# AST1080 register map
File version: 1.0
CPU: CM4 r0p1, little endian, MPU, FPU, 4 interrupt priority bits, 256 interrupts
Registers are 32-bit, read-write, reset 0x0 unless marked. A register's access mark holds for its fields unless they carry their own. Offsets are from the block's base; [hi:lo] are bit positions; {n}, {i} and the like mark numbered series.

## i3c
Base 0x74C20000
Same registers: i3c1 0x74C21000, i3c2 0x74C22000, i3c3 0x74C23000, i3c4 0x74C24000, i3c5 0x74C25000, i3c6 0x74C26000, i3c7 0x74C27000
0x00 HCICAPABILITY000 reset 0x110 — HCI\_VERSION
  [31:0] REGHCIVERSION ro
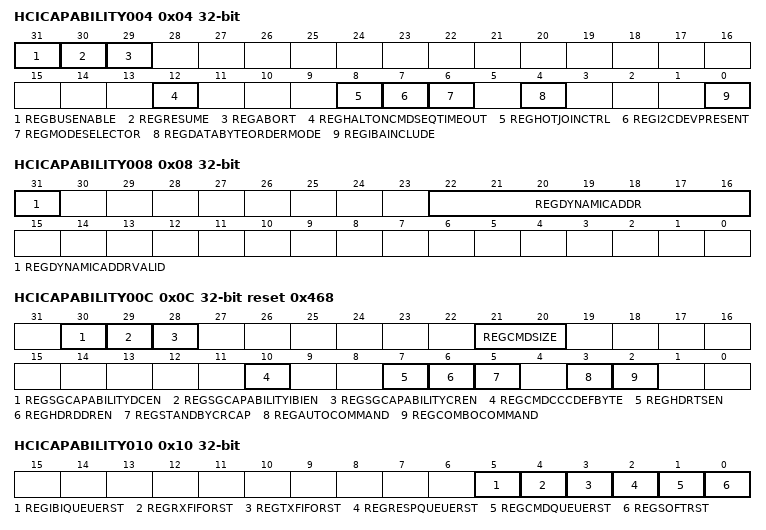
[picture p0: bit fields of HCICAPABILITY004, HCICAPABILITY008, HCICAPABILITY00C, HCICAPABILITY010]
0x04 HCICAPABILITY004 — HC\_CONTROL
  [31] REGBUSENABLE, [30] REGRESUME, [29] REGABORT, [12] REGHALTONCMDSEQTIMEOUT, [8] REGHOTJOINCTRL, [7] REGI2CDEVPRESENT, [6] REGMODESELECTOR, [4] REGDATABYTEORDERMODE ro, [0] REGIBAINCLUDE
0x08 HCICAPABILITY008 — CONTROLLER\_DEVICE\_ADDR
  [31] REGDYNAMICADDRVALID, [22:16] REGDYNAMICADDR
0x0C HCICAPABILITY00C reset 0x468 — HC\_CAPABILITIES
  [30] REGSGCAPABILITYDCEN ro, [29] REGSGCAPABILITYIBIEN ro, [28] REGSGCAPABILITYCREN ro, [21:20] REGCMDSIZE ro, [10] REGCMDCCCDEFBYTE ro, [7] REGHDRTSEN ro, [6] REGHDRDDREN ro, [5] REGSTANDBYCRCAP ro, [3] REGAUTOCOMMAND ro, [2] REGCOMBOCOMMAND ro
0x10 HCICAPABILITY010 — RESET\_CONTROL
  [5] REGIBIQUEUERST, [4] REGRXFIFORST, [3] REGTXFIFORST, [2] REGRESPQUEUERST, [1] REGCMDQUEUERST, [0] REGSOFTRST
0x14 HCICAPABILITY014 — PRESENT\_STATE
  [2] REGCURRENTCONTROLLER ro
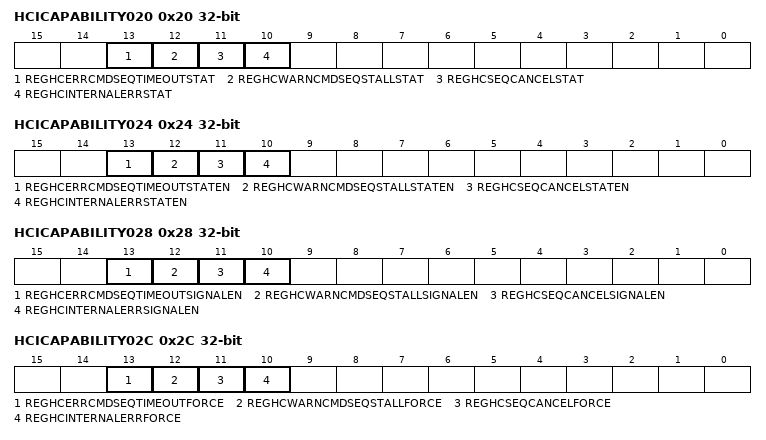
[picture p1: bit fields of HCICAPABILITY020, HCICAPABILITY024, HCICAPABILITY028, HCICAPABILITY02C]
0x20 HCICAPABILITY020 — INTR\_STATUS
  [13] REGHCERRCMDSEQTIMEOUTSTAT, [12] REGHCWARNCMDSEQSTALLSTAT, [11] REGHCSEQCANCELSTAT, [10] REGHCINTERNALERRSTAT
0x24 HCICAPABILITY024 — INTR\_STATUS\_ENABLE
  [13] REGHCERRCMDSEQTIMEOUTSTATEN, [12] REGHCWARNCMDSEQSTALLSTATEN, [11] REGHCSEQCANCELSTATEN, [10] REGHCINTERNALERRSTATEN
0x28 HCICAPABILITY028 — INTR\_SIGNAL\_ENABLE
  [13] REGHCERRCMDSEQTIMEOUTSIGNALEN, [12] REGHCWARNCMDSEQSTALLSIGNALEN, [11] REGHCSEQCANCELSIGNALEN, [10] REGHCINTERNALERRSIGNALEN
0x2C HCICAPABILITY02C — INTR\_FORCE
  [13] REGHCERRCMDSEQTIMEOUTFORCE, [12] REGHCWARNCMDSEQSTALLFORCE, [11] REGHCSEQCANCELFORCE, [10] REGHCINTERNALERRFORCE
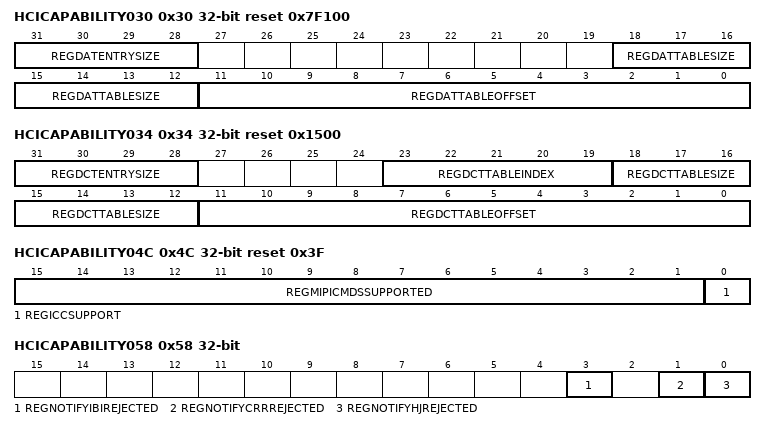
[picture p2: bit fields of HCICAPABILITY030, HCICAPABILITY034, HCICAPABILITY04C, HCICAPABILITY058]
0x30 HCICAPABILITY030 reset 0x7F100 — DAT\_SECTION\_OFFSET
  [31:28] REGDATENTRYSIZE ro, [18:12] REGDATTABLESIZE ro, [11:0] REGDATTABLEOFFSET ro
0x34 HCICAPABILITY034 reset 0x1500 — DCT\_SECTION\_OFFSET
  [31:28] REGDCTENTRYSIZE ro, [23:19] REGDCTTABLEINDEX, [18:12] REGDCTTABLESIZE ro, [11:0] REGDCTTABLEOFFSET ro
0x38 HCICAPABILITY038 reset 0x800 — RING\_HEADERS\_SECTION\_OFFSET
  [15:0] REGRINGHEADERSECTIONOFFSET ro
0x3C HCICAPABILITY03C reset 0xD0 — PIO\_SECTION\_OFFSET
  [15:0] REGPIOSECTIONOFFSET ro
0x40 HCICAPABILITY040 reset 0xF00 — EXT\_CAPS\_SECTION\_OFFSET
  [15:0] REGEXTCAPSSECTIONOFFSET ro
0x4C HCICAPABILITY04C reset 0x3F — INT\_CTRL\_CMDS\_EN
  [15:1] REGMIPICMDSSUPPORTED ro, [0] REGICCSUPPORT ro
0x58 HCICAPABILITY058 — IBI\_NOTIFY\_CTRL
  [3] REGNOTIFYIBIREJECTED, [1] REGNOTIFYCRRREJECTED, [0] REGNOTIFYHJREJECTED
0x60 HCICAPABILITY060 — DEV\_CTX\_BASE\_LO
  [31:0] REGDEVCTXBASELO
0x64 HCICAPABILITY064 — DEV\_CTX\_BASE\_HI
  [31:0] REGDEVCTXBASEHI
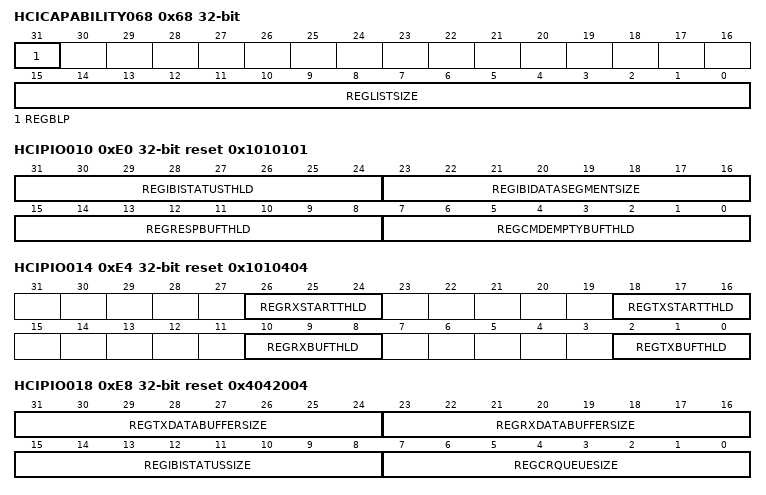
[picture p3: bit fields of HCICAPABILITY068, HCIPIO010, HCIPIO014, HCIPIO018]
0x68 HCICAPABILITY068 — DEV\_CTX\_SG
  [31] REGBLP, [15:0] REGLISTSIZE
0xD0 HCIPIO000 — COMMAND\_QUEUE\_PORT
  [31:0] REGCOMMANDQUEUEPORT
0xD4 HCIPIO004 — RESPONSE\_QUEUE\_PORT
  [31:0] REGRESPONSEQUEUEPORT ro
0xD8 HCIPIO008 — XFER\_DATA\_PORT
  [31:0] REGDATAPORT
0xDC HCIPIO00C — IBI\_PORT
  [31:0] REGIBIPORT ro
0xE0 HCIPIO010 reset 0x1010101 — QUEUE\_THLD\_CTRL
  [31:24] REGIBISTATUSTHLD, [23:16] REGIBIDATASEGMENTSIZE, [15:8] REGRESPBUFTHLD, [7:0] REGCMDEMPTYBUFTHLD
0xE4 HCIPIO014 reset 0x1010404 — DATA\_BUFFER\_THLD\_CTRL
  [26:24] REGRXSTARTTHLD, [18:16] REGTXSTARTTHLD, [10:8] REGRXBUFTHLD, [2:0] REGTXBUFTHLD
0xE8 HCIPIO018 reset 0x4042004 — QUEUE\_SIZE
  [31:24] REGTXDATABUFFERSIZE ro, [23:16] REGRXDATABUFFERSIZE ro, [15:8] REGIBISTATUSSIZE ro, [7:0] REGCRQUEUESIZE ro
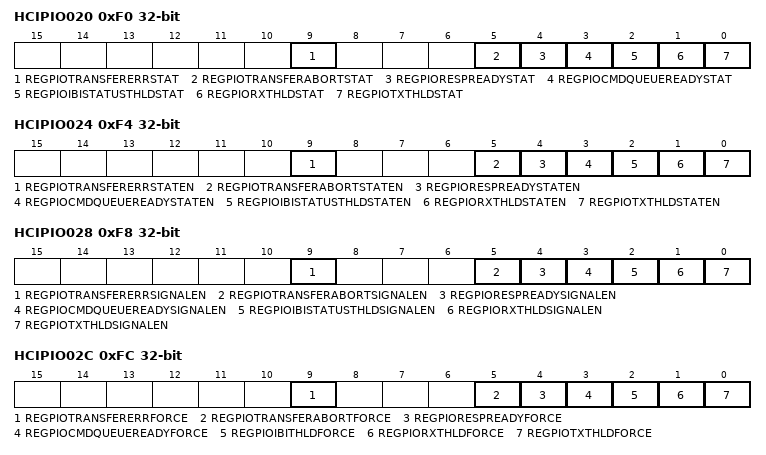
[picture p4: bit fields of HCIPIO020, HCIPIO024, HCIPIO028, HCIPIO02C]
0xF0 HCIPIO020 — PIO\_INTR\_STATUS
  [9] REGPIOTRANSFERERRSTAT, [5] REGPIOTRANSFERABORTSTAT, [4] REGPIORESPREADYSTAT ro, [3] REGPIOCMDQUEUEREADYSTAT ro, [2] REGPIOIBISTATUSTHLDSTAT ro, [1] REGPIORXTHLDSTAT ro, [0] REGPIOTXTHLDSTAT ro
0xF4 HCIPIO024 — PIO\_INTR\_STATUS\_ENABLE
  [9] REGPIOTRANSFERERRSTATEN, [5] REGPIOTRANSFERABORTSTATEN, [4] REGPIORESPREADYSTATEN, [3] REGPIOCMDQUEUEREADYSTATEN, [2] REGPIOIBISTATUSTHLDSTATEN, [1] REGPIORXTHLDSTATEN, [0] REGPIOTXTHLDSTATEN
0xF8 HCIPIO028 — PIO\_INTR\_SIGNAL\_ENABLE
  [9] REGPIOTRANSFERERRSIGNALEN, [5] REGPIOTRANSFERABORTSIGNALEN, [4] REGPIORESPREADYSIGNALEN, [3] REGPIOCMDQUEUEREADYSIGNALEN, [2] REGPIOIBISTATUSTHLDSIGNALEN, [1] REGPIORXTHLDSIGNALEN, [0] REGPIOTXTHLDSIGNALEN
0xFC HCIPIO02C — PIO\_INTR\_FORCE
  [9] REGPIOTRANSFERERRFORCE, [5] REGPIOTRANSFERABORTFORCE, [4] REGPIORESPREADYFORCE, [3] REGPIOCMDQUEUEREADYFORCE, [2] REGPIOIBITHLDFORCE, [1] REGPIORXTHLDFORCE, [0] REGPIOTXTHLDFORCE
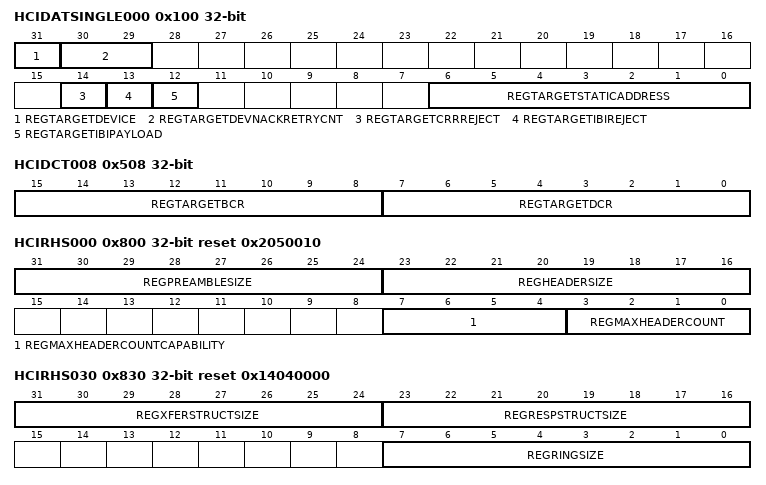
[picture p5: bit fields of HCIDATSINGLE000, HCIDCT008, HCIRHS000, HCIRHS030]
0x100 HCIDATSINGLE000 — TARGET\_DAT
  [31] REGTARGETDEVICE, [30:29] REGTARGETDEVNACKRETRYCNT, [14] REGTARGETCRRREJECT, [13] REGTARGETIBIREJECT, [12] REGTARGETIBIPAYLOAD, [6:0] REGTARGETSTATICADDRESS
0x500 HCIDCT000 — TARGET\_DCT\_0
  [31:0] REGTARGETPIDHI ro
0x504 HCIDCT004 — TARGET\_DCT\_1
  [15:0] REGTARGETPIDLO ro
0x508 HCIDCT008 — TARGET\_DCT\_2
  [15:8] REGTARGETBCR ro, [7:0] REGTARGETDCR ro
0x50C HCIDCT00C — TARGET\_DCT\_3
  [7:0] REGTARGETDYNAMICADDRESS ro
0x800 HCIRHS000 reset 0x2050010 — RHS\_CONTROL
  [31:24] REGPREAMBLESIZE ro, [23:16] REGHEADERSIZE ro, [7:4] REGMAXHEADERCOUNTCAPABILITY ro, [3:0] REGMAXHEADERCOUNT
0x804 HCIRHS004 reset 0x830 — RH0\_OFFSET
  [31:0] REGRH0OFFSET ro
0x830 HCIRHS030 reset 0x14040000 — CR\_SETUP
  [31:24] REGXFERSTRUCTSIZE ro, [23:16] REGRESPSTRUCTSIZE ro, [7:0] REGRINGSIZE
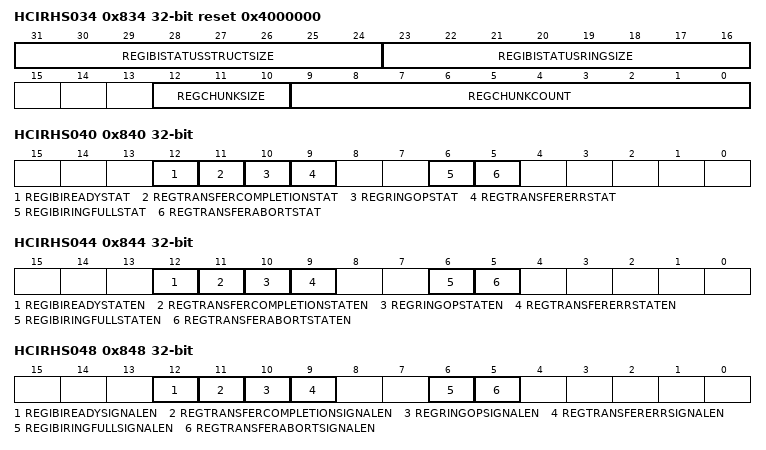
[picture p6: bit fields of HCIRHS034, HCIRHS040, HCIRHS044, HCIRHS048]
0x834 HCIRHS034 reset 0x4000000 — IBI\_SETUP
  [31:24] REGIBISTATUSSTRUCTSIZE ro, [23:16] REGIBISTATUSRINGSIZE, [12:10] REGCHUNKSIZE, [9:0] REGCHUNKCOUNT
0x838 HCIRHS038 — CHUNK\_CONTROL
  [31:0] REGCHUNKCOUNTER
0x840 HCIRHS040 — RH\_INTR\_STATUS
  [12] REGIBIREADYSTAT, [11] REGTRANSFERCOMPLETIONSTAT, [10] REGRINGOPSTAT, [9] REGTRANSFERERRSTAT, [6] REGIBIRINGFULLSTAT, [5] REGTRANSFERABORTSTAT
0x844 HCIRHS044 — RH\_INTR\_STATUS\_ENABLE
  [12] REGIBIREADYSTATEN, [11] REGTRANSFERCOMPLETIONSTATEN, [10] REGRINGOPSTATEN, [9] REGTRANSFERERRSTATEN, [6] REGIBIRINGFULLSTATEN, [5] REGTRANSFERABORTSTATEN
0x848 HCIRHS048 — RH\_INTR\_SIGNAL\_ENABLE
  [12] REGIBIREADYSIGNALEN, [11] REGTRANSFERCOMPLETIONSIGNALEN, [10] REGRINGOPSIGNALEN, [9] REGTRANSFERERRSIGNALEN, [6] REGIBIRINGFULLSIGNALEN, [5] REGTRANSFERABORTSIGNALEN
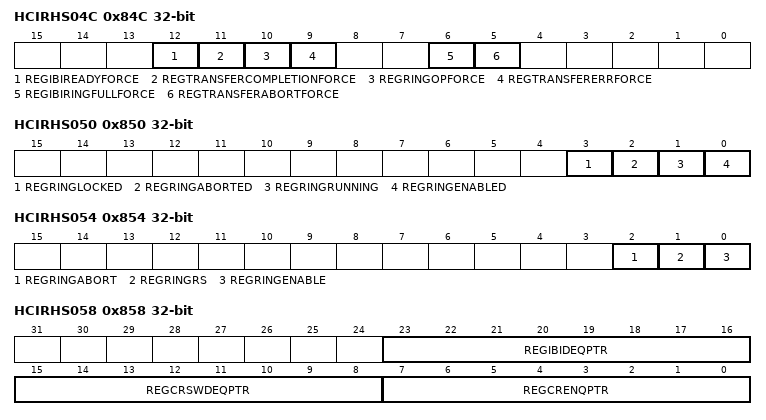
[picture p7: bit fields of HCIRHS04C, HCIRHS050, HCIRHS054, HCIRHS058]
0x84C HCIRHS04C — RH\_INTR\_FORCE
  [12] REGIBIREADYFORCE, [11] REGTRANSFERCOMPLETIONFORCE, [10] REGRINGOPFORCE, [9] REGTRANSFERERRFORCE, [6] REGIBIRINGFULLFORCE, [5] REGTRANSFERABORTFORCE
0x850 HCIRHS050 — RH\_STATUS
  [3] REGRINGLOCKED ro, [2] REGRINGABORTED ro, [1] REGRINGRUNNING ro, [0] REGRINGENABLED ro
0x854 HCIRHS054 — RH\_CONTROL
  [2] REGRINGABORT, [1] REGRINGRS, [0] REGRINGENABLE
0x858 HCIRHS058 — RH\_OPERATION1
  [23:16] REGIBIDEQPTR, [15:8] REGCRSWDEQPTR, [7:0] REGCRENQPTR
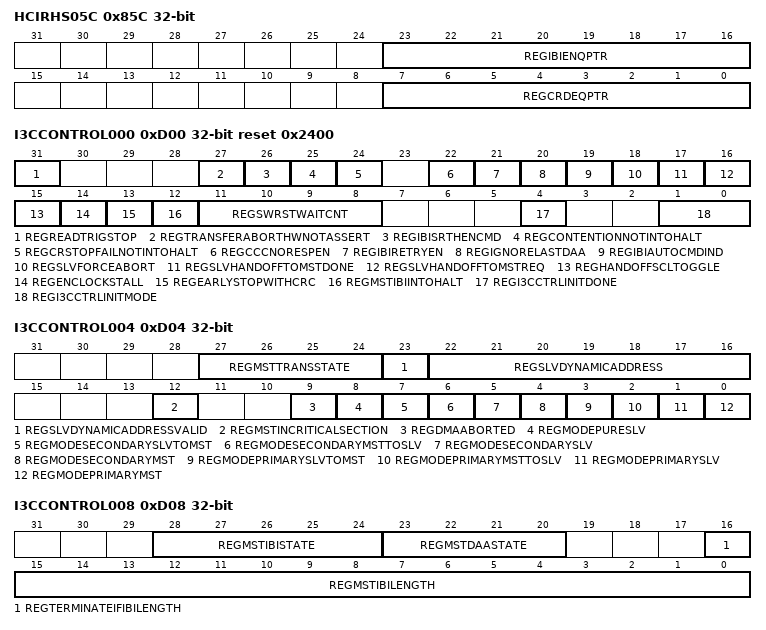
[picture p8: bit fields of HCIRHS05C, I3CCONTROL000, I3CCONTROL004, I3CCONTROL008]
0x85C HCIRHS05C — RH\_OPERATION2
  [23:16] REGIBIENQPTR ro, [7:0] REGCRDEQPTR ro
0x860 HCIRHS060 — RH\_CMD\_RING\_BASE\_LO
  [31:0] REGCMDRINGBASELO
0x864 HCIRHS064 — RH\_CMD\_RING\_BASE\_HI
  [31:0] REGCMDRINGBASEHI
0x868 HCIRHS068 — RH\_RESP\_RING\_BASE\_LO
  [31:0] REGRESPRINGBASELO
0x86C HCIRHS06C — RH\_RESP\_RING\_BASE\_HI
  [31:0] REGRESPRINGBASEHI
0x870 HCIRHS070 — RH\_IBI\_STATUS\_RING\_BASE\_LO
  [31:0] REGIBISTATUSRINGBASELO
0x874 HCIRHS074 — RH\_IBI\_STATUS\_RING\_BASE\_HI
  [31:0] REGIBISTATUSRINGBASEHI
0x878 HCIRHS078 — RH\_IBI\_DATA\_RING\_BASE\_LO
  [31:0] REGIBIDATARINGBASELO
0x87C HCIRHS07C — RH\_IBI\_DATA\_RING\_BASE\_HI
  [31:0] REGIBIDATARINGBASEHI
0xD00 I3CCONTROL000 reset 0x2400 — I3C\_CONTROL\_0
  [31] REGREADTRIGSTOP, [27] REGTRANSFERABORTHWNOTASSERT, [26] REGIBISRTHENCMD, [25] REGCONTENTIONNOTINTOHALT, [24] REGCRSTOPFAILNOTINTOHALT, [22] REGCCCNORESPEN, [21] REGIBIRETRYEN, [20] REGIGNORELASTDAA, [19] REGIBIAUTOCMDIND, [18] REGSLVFORCEABORT, [17] REGSLVHANDOFFTOMSTDONE ro, [16] REGSLVHANDOFFTOMSTREQ, [15] REGHANDOFFSCLTOGGLE, [14] REGENCLOCKSTALL, [13] REGEARLYSTOPWITHCRC, [12] REGMSTIBIINTOHALT, [11:8] REGSWRSTWAITCNT, [4] REGI3CCTRLINITDONE, [1:0] REGI3CCTRLINITMODE
0xD04 I3CCONTROL004 — I3C\_STATUS
  [27:24] REGMSTTRANSSTATE ro, [23] REGSLVDYNAMICADDRESSVALID ro, [22:16] REGSLVDYNAMICADDRESS ro, [12] REGMSTINCRITICALSECTION ro, [9] REGDMAABORTED ro, [8] REGMODEPURESLV ro, [7] REGMODESECONDARYSLVTOMST ro, [6] REGMODESECONDARYMSTTOSLV ro, [5] REGMODESECONDARYSLV ro, [4] REGMODESECONDARYMST ro, [3] REGMODEPRIMARYSLVTOMST ro, [2] REGMODEPRIMARYMSTTOSLV ro, [1] REGMODEPRIMARYSLV ro, [0] REGMODEPRIMARYMST ro
0xD08 I3CCONTROL008 — I3C\_MST\_MRL
  [28:24] REGMSTIBISTATE ro, [23:20] REGMSTDAASTATE ro, [16] REGTERMINATEIFIBILENGTH, [15:0] REGMSTIBILENGTH
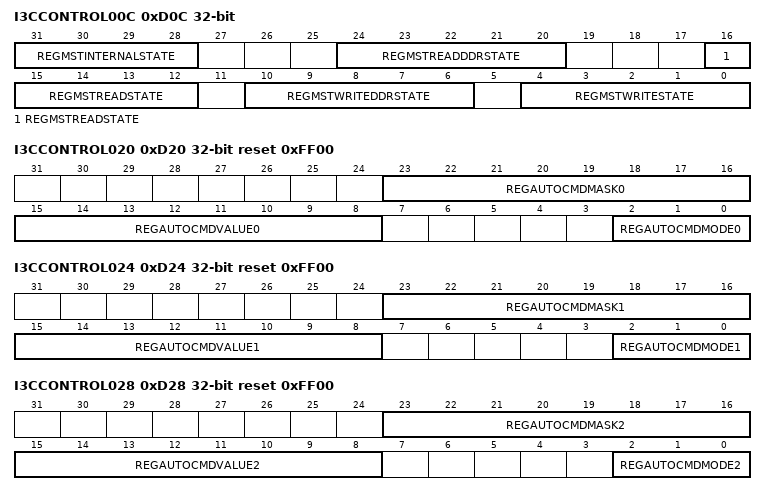
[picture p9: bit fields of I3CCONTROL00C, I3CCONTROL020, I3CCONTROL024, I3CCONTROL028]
0xD0C I3CCONTROL00C — I3C\_STATUS\_C
  [31:28] REGMSTINTERNALSTATE ro, [24:20] REGMSTREADDDRSTATE ro, [16:12] REGMSTREADSTATE ro, [10:6] REGMSTWRITEDDRSTATE ro, [4:0] REGMSTWRITESTATE ro
0xD10 I3CCONTROL010 — I3C\_DAA\_INDEX\_0
  [31:0] REGDAAPROCINDEX0
0xD14 I3CCONTROL014 — I3C\_DAA\_INDEX\_1
  [31:0] REGDAAPROCINDEX1
0xD18 I3CCONTROL018 — I3C\_DAA\_INDEX\_2
  [31:0] REGDAAPROCINDEX2
0xD1C I3CCONTROL01C — I3C\_DAA\_INDEX\_3
  [31:0] REGDAAPROCINDEX3
0xD20 I3CCONTROL020 reset 0xFF00 — I3C\_AUTOCMD\_0
  [23:16] REGAUTOCMDMASK0, [15:8] REGAUTOCMDVALUE0, [2:0] REGAUTOCMDMODE0
0xD24 I3CCONTROL024 reset 0xFF00 — I3C\_AUTOCMD\_1
  [23:16] REGAUTOCMDMASK1, [15:8] REGAUTOCMDVALUE1, [2:0] REGAUTOCMDMODE1
0xD28 I3CCONTROL028 reset 0xFF00 — I3C\_AUTOCMD\_2
  [23:16] REGAUTOCMDMASK2, [15:8] REGAUTOCMDVALUE2, [2:0] REGAUTOCMDMODE2
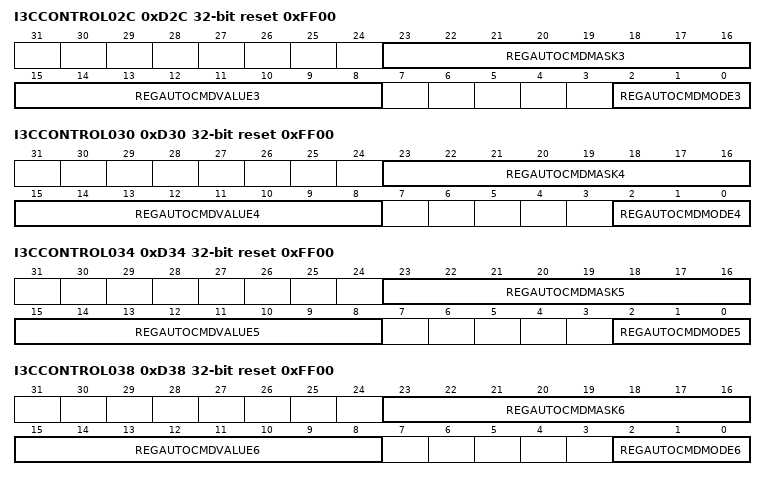
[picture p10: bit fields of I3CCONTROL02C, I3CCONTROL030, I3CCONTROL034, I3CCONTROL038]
0xD2C I3CCONTROL02C reset 0xFF00 — I3C\_AUTOCMD\_3
  [23:16] REGAUTOCMDMASK3, [15:8] REGAUTOCMDVALUE3, [2:0] REGAUTOCMDMODE3
0xD30 I3CCONTROL030 reset 0xFF00 — I3C\_AUTOCMD\_4
  [23:16] REGAUTOCMDMASK4, [15:8] REGAUTOCMDVALUE4, [2:0] REGAUTOCMDMODE4
0xD34 I3CCONTROL034 reset 0xFF00 — I3C\_AUTOCMD\_5
  [23:16] REGAUTOCMDMASK5, [15:8] REGAUTOCMDVALUE5, [2:0] REGAUTOCMDMODE5
0xD38 I3CCONTROL038 reset 0xFF00 — I3C\_AUTOCMD\_6
  [23:16] REGAUTOCMDMASK6, [15:8] REGAUTOCMDVALUE6, [2:0] REGAUTOCMDMODE6
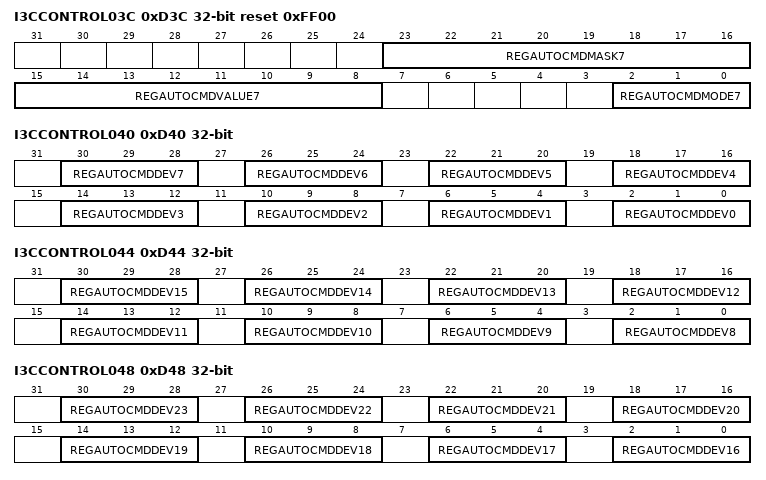
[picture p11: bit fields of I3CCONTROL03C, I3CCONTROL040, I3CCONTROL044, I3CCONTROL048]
0xD3C I3CCONTROL03C reset 0xFF00 — I3C\_AUTOCMD\_7
  [23:16] REGAUTOCMDMASK7, [15:8] REGAUTOCMDVALUE7, [2:0] REGAUTOCMDMODE7
0xD40 I3CCONTROL040 — I3C\_AUTOCMD\_SEL\_040
  [4n+2:4n] REGAUTOCMDDEV{n} (n=0..7)
0xD44 I3CCONTROL044 — I3C\_AUTOCMD\_SEL\_044
  [4n-30:4n-32] REGAUTOCMDDEV{n} (n=8..15)
0xD48 I3CCONTROL048 — I3C\_AUTOCMD\_SEL\_048
  [4n-62:4n-64] REGAUTOCMDDEV{n} (n=16..23)
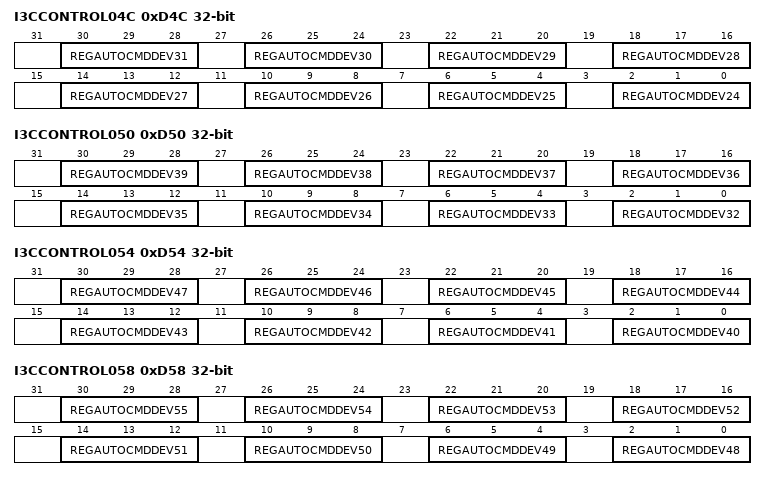
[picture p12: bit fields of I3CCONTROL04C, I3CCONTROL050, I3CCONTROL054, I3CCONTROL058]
0xD4C I3CCONTROL04C — I3C\_AUTOCMD\_SEL\_04C
  [4n-94:4n-96] REGAUTOCMDDEV{n} (n=24..31)
0xD50 I3CCONTROL050 — I3C\_AUTOCMD\_SEL\_050
  [4n-126:4n-128] REGAUTOCMDDEV{n} (n=32..39)
0xD54 I3CCONTROL054 — I3C\_AUTOCMD\_SEL\_054
  [4n-158:4n-160] REGAUTOCMDDEV{n} (n=40..47)
0xD58 I3CCONTROL058 — I3C\_AUTOCMD\_SEL\_058
  [4n-190:4n-192] REGAUTOCMDDEV{n} (n=48..55)
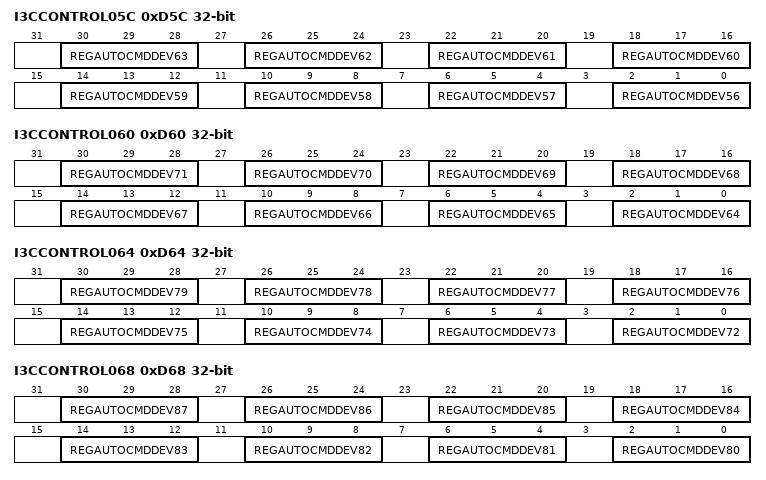
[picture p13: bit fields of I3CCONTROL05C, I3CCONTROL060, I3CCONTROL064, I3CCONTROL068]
0xD5C I3CCONTROL05C — I3C\_AUTOCMD\_SEL\_05C
  [4n-222:4n-224] REGAUTOCMDDEV{n} (n=56..63)
0xD60 I3CCONTROL060 — I3C\_AUTOCMD\_SEL\_060
  [4n-254:4n-256] REGAUTOCMDDEV{n} (n=64..71)
0xD64 I3CCONTROL064 — I3C\_AUTOCMD\_SEL\_064
  [4n-286:4n-288] REGAUTOCMDDEV{n} (n=72..79)
0xD68 I3CCONTROL068 — I3C\_AUTOCMD\_SEL\_068
  [4n-318:4n-320] REGAUTOCMDDEV{n} (n=80..87)
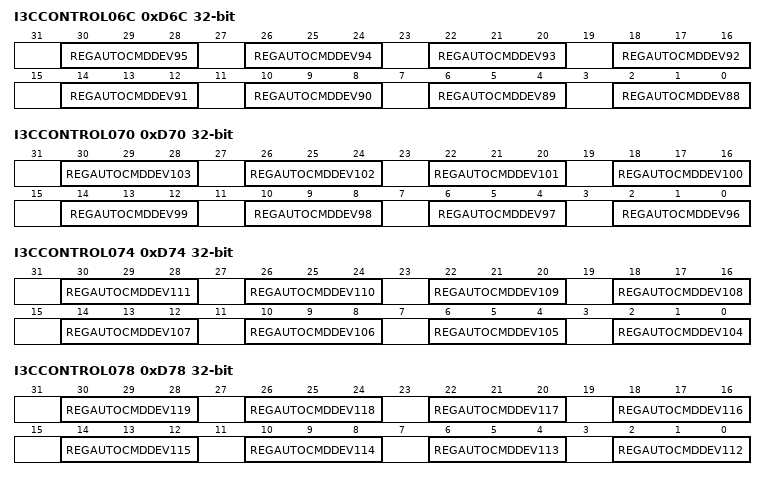
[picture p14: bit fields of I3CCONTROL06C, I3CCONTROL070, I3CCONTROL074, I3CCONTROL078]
0xD6C I3CCONTROL06C — I3C\_AUTOCMD\_SEL\_06C
  [4n-350:4n-352] REGAUTOCMDDEV{n} (n=88..95)
0xD70 I3CCONTROL070 — I3C\_AUTOCMD\_SEL\_070
  [4n-382:4n-384] REGAUTOCMDDEV{n} (n=96..103)
0xD74 I3CCONTROL074 — I3C\_AUTOCMD\_SEL\_074
  [4n-414:4n-416] REGAUTOCMDDEV{n} (n=104..111)
0xD78 I3CCONTROL078 — I3C\_AUTOCMD\_SEL\_078
  [4n-446:4n-448] REGAUTOCMDDEV{n} (n=112..119)
0xD7C I3CCONTROL07C — I3C\_AUTOCMD\_SEL\_07C
  [4n-478:4n-480] REGAUTOCMDDEV{n} (n=120..127)
0xD80 I3CCONTROL080 reset 0x3800000 — I3C\_WDMA\_CTL\_080
  [31:24] REGRINGWDMALENTH, [23:16] REGRINGWDMACNTTH, [0] REGRINGWDMASWCLR
0xD84 I3CCONTROL084 — I3C\_WDMA\_CTL\_084
  [31:0] REGRINGWDMADBGLO ro
0xD88 I3CCONTROL088 — I3C\_WDMA\_CTL\_088
  [31:0] REGRINGWDMADBGHI ro
0xD90 I3CCONTROL090 reset 0x3800000 — I3C\_RDMA\_CTL\_090
  [31:24] REGRINGRDMALENTH, [23:16] REGRINGRDMACNTTH, [0] REGRINGRDMASWCLR
0xD94 I3CCONTROL094 — I3C\_RDMA\_CTL\_094
  [31:0] REGRINGRDMADBGLO ro
0xD98 I3CCONTROL098 — I3C\_RDMA\_CTL\_098
  [31:0] REGRINGRDMADBGHI ro
0xD9C I3CCONTROL09C — I3C\_RING\_CTL\_09C
  [4:0] REGRINGPROCESSSTATE ro
0xDA0 I3CCONTROL0A0 — I3C\_SLV\_CTL\_0A0
  [23:16] REGSLVDCR, [15:8] REGSLVBCR, [7] REGSTATICADDREN, [6:0] REGSTATICADDR
0xDA4 I3CCONTROL0A4 — I3C\_SLV\_CTL\_0A4
  [31:0] REGSLVPID
0xDA8 I3CCONTROL0A8 — I3C\_SLV\_CTL\_0A8
  [15:0] REGSLVPIDHI
0xDAC I3CCONTROL0AC — I3C\_SLV\_CTL\_0AC
  [5:0] REGSLVTRANSSTATE ro
0xDB0 I3CCONTROL0B0 reset 0x10000 — I3C\_SLV\_CTL\_0B0
  [30] REGSLVIBIHALTIFERROR, [21] REGSLVCMDATTREN, [20] REGSLVCCCNORESP, [16] REGACCEPTCR, [10] REGHJREQUEST, [9] REGMRREQUEST, [8] REGIBIREQUEST, [7] REGHJWAIT7E, [6] REGHJWAITIDLE, [5] REGMRWAITAVAILABLE, [4] REGIBIWAITAVAILABLE, [1] REGNOCCCDEFINING, [0] REGI2CDEVICE
0xDB4 I3CCONTROL0B4 reset 0x10070 — I3C\_SLV\_CTL\_0B4
  [31:24] REGIBIPAYLOADSIZE ro, [22:16] REGRSTACTDEFINE ro, [15] REGENDXFERACKCAP ro, [14] REGENDXFERENWET ro, [13:12] REGENDXFERCRCWORD ro, [11] REGENDXFERCONFIRM ro, [10] REGSLVINBUSY ro, [8] REGENTTM ro, [6] REGENHJ, [5] REGENCR, [4] REGENINT, [2] REGHJDONE ro, [1] REGMRDONE ro, [0] REGIBIDONE ro
0xDB8 I3CCONTROL0B8 reset 0x800080 — I3C\_SLV\_CTL\_0B8
  [31:16] REGMWL, [15:0] REGMRL
0xDBC I3CCONTROL0BC — I3C\_SLV\_CTL\_0BC
  [8n+7] GROUPADDR{n}VALID ro (n=0..3), [8n+6:8n] GROUPADDR{n} ro (n=0..3)
0xDC0 I3CCONTROL0C0 — I3C\_SLV\_CTL\_0C0
  [23:16] REGRSTDBGNETWORKTIME, [15:8] REGRSTWHOLECHIPTIME, [7:0] REGRSTI3CTIME
0xDC4 I3CCONTROL0C4 — I3C\_SLV\_CTL\_0C4
  [15:8] REGGETMXDSMAXWR, [7:0] REGGETMXDSMAXRD
0xDC8 I3CCONTROL0C8 — I3C\_SLV\_CTL\_0C8
  [25] REGPENDINGINTHW, [24] REGGETMXDSEN, [23:16] REGGETMXDSMAXRDTURNH, [15:8] REGGETMXDSMAXRDTURNM, [7:0] REGGETMXDSMAXRDTURNL
0xDCC I3CCONTROL0CC — I3C\_SLV\_CTL\_0CC
  [31:16] REGGETSTATUSPRECR, [15:0] REGGETSTATUSTGTSTAT
0xDD0 I3CCONTROL0D0 — I3C\_SLV\_CTL\_0D0
  [31:0] REGGETCAPSTGTCAPS
0xDD4 I3CCONTROL0D4 — I3C\_SLV\_CTL\_0D4
  [31:16] REGGETCAPSVTCAPS, [15:0] REGGETCAPSCRCAPS
0xDD8 I3CCONTROL0D8 — I3C\_QUEUE\_PTR\_0D8
  [24:20] REGTXQUERPTR ro, [16:12] REGTXQUEWPTR ro, [11:10] REGIBISTSQUERPTR ro, [9:8] REGIBISTSQUEWPTR ro, [7:6] REGRESPQUERPTR ro, [5:4] REGRESPQUEWPTR ro, [3:2] REGCMDQUERPTR ro, [1:0] REGCMDQUEWPTR ro
0xDDC I3CCONTROL0DC — I3C\_QUEUE\_PTR\_0DC
  [28:24] REGIBIDATQUERPTR ro, [20:16] REGIBIDATQUEWPTR ro, [12:8] REGRXQUERPTR ro, [4:0] REGRXQUEWPTR ro
0xDE0 I3CCONTROL0E0 — I3C\_INTR\_STATUS
  [21] REGIBIENQPTRDIFFSTAT ro, [20] REGCRDEQPTRDIFFSTAT ro, [18] REGDDRBUSCDSTAT, [17] REGSDRBUSCDSTAT, [16] REGROLECHANGESTAT, [15] REGDETCRSTOPFAILSTAT, [10] REGMSTINTERNALDONESTAT, [9] REGMSTDDRREADDONESTAT, [8] REGMSTDDRWRITEDONESTAT, [7] REGMSTIBIDONESTAT, [6] REGMSTREADDONESTAT, [5] REGMSTWRITEDONESTAT, [4] REGMSTDAADONESTAT, [1] REGSLVSCLSTUCKSTAT, [0] REGTGRSTSTAT
0xDE4 I3CCONTROL0E4 — I3C\_INTR\_STATUS\_ENABLE
  [21] REGIBIENQPTRDIFFSTATEN, [20] REGCRDEQPTRDIFFSTATEN, [18] REGDDRBUSCDSTATEN, [17] REGSDRBUSCDSTATEN, [16] REGROLECHANGESTATEN, [15] REGDETCRSTOPFAILSTATEN, [10] REGMSTINTERNALDONESTATEN, [9] REGMSTDDRREADDONESTATEN, [8] REGMSTDDRWRITEDONESTATEN, [7] REGMSTIBIDONESTATEN, [6] REGMSTREADDONESTATEN, [5] REGMSTWRITEDONESTATEN, [4] REGMSTDAADONESTATEN, [1] REGSLVSCLSTUCKSTATEN, [0] REGTGRSTSTATEN
0xDE8 I3CCONTROL0E8 — I3C\_INTR\_SIGNAL\_ENABLE
  [21] REGIBIENQPTRDIFFSIGNALEN, [20] REGCRDEQPTRDIFFSIGNALEN, [18] REGDDRBUSCDSIGNALEN, [17] REGSDRBUSCDSIGNALEN, [16] REGROLECHANGESIGNALEN, [15] REGDETCRSTOPFAILSIGNALEN, [10] REGMSTINTERNALDONESIGNALEN, [9] REGMSTDDRREADDONESIGNALEN, [8] REGMSTDDRWRITEDONESIGNALEN, [7] REGMSTIBIDONESIGNALEN, [6] REGMSTREADDONESIGNALEN, [5] REGMSTWRITEDONESIGNALEN, [4] REGMSTDAADONESIGNALEN, [1] REGSLVSCLSTUCKSIGNALEN, [0] REGTGRSTSIGNALEN
0xDEC I3CCONTROL0EC — I3C\_INTR\_FORCE
  [21] REGIBIENQPTRDIFFFORCE, [20] REGCRDEQPTRDIFFFORCE, [18] REGDDRBUSCDFORCE, [17] REGSDRBUSCDFORCE, [16] REGROLECHANGEFORCE, [15] REGDETCRSTOPFAILFORCE, [10] REGMSTINTERNALDONEFORCE, [9] REGMSTDDRREADDONEFORCE, [8] REGMSTDDRWRITEDONEFORCE, [7] REGMSTIBIDONEFORCE, [6] REGMSTREADDONEFORCE, [5] REGMSTWRITEDONEFORCE, [4] REGMSTDAADONEFORCE, [1] REGSLVSCLSTUCKFORCE, [0] REGTGRSTFORCE
0xDF0 I3CCONTROL0F0 — I3C\_INTR\_STATUS\_F0
  [3] REGINHOUSESTATUS ro, [2] REGRHSSTATUS ro, [1] REGPIOSTATUS ro, [0] REGCAPSTATUS ro
0xDF4 I3CCONTROL0F4 — I3C\_INTR\_PROCESS
  [0] REGI3CINTRPROCESS
0xDF8 I3CCONTROL0F8 reset 0xEA60 — I3C\_IBI\_TIMEOUT\_F8
  [16] REGIBITIMEOUTEN, [15:0] REGIBITIMEOUT
0xE00 I3CPHYCTRLREG000 reset 0x100 — EXT\_CAP\_OFFSET
  [23:8] REGI3CPHYCAPLENGTH ro, [7:0] REGI3CPHYCAPID ro
0xE04 I3CPHYCTRLREG004 reset 0x3737 — SW\_CTRL
  [31:24] REGSWENABLE, [13] REGSWSCLI, [12] REGSWSCLO, [11] REGSWSCLOE, [10:8] REGSWSCLPULLUPEN, [5] REGSWSDAI, [4] REGSWSDAO, [3] REGSWSDAOE, [2:0] REGSWSDAPULLUPEN
0xE08 I3CPHYCTRLREG008 reset 0x770103 — CR\_I2C\_OD\_FM\_STA\_STO\_CNT
  [26:16] REGI2CODFMSTARTHCNT, [10:0] REGI2CODFMSTOPHCNT
0xE0C I3CPHYCTRLREG00C reset 0x770103 — CR\_I2C\_OD\_FM\_SCL\_CNT
  [26:16] REGI2CODFMHCNT, [10:0] REGI2CODFMLCNT
0xE10 I3CPHYCTRLREG010 reset 0x770103 — CR\_I2C\_OD\_FM\_ACK\_CNT
  [26:16] REGI2CODFMACKHCNT, [10:0] REGI2CODFMACKLCNT
0xE14 I3CPHYCTRLREG014 reset 0x10001 — CR\_I2C\_OD\_FM\_SDA\_TRAN\_CNT
  [26:16] REGI2CODFMSDATRANCNT, [10:0] REGI2CODFMSDAACKTRANCNT
0xE18 I3CPHYCTRLREG018 reset 0x330063 — CR\_I2C\_OD\_FMP\_STA\_STO\_CNT
  [26:16] REGI2CODFMPSTARTHCNT, [10:0] REGI2CODFMPSTOPHCNT
0xE1C I3CPHYCTRLREG01C reset 0x330063 — CR\_I2C\_OD\_FMP\_SCL\_CNT
  [26:16] REGI2CODFMPHCNT, [10:0] REGI2CODFMPLCNT
0xE20 I3CPHYCTRLREG020 reset 0x330063 — CR\_I2C\_OD\_FMP\_ACK\_CNT
  [26:16] REGI2CODFMPACKHCNT, [10:0] REGI2CODFMPACKLCNT
0xE24 I3CPHYCTRLREG024 reset 0x10001 — CR\_I2C\_OD\_FMP\_SDA\_TRAN\_CNT
  [26:16] REGI2CODFMPSDATRANCNT, [10:0] REGI2CODFMPSDAACKTRANCNT
0xE28 I3CPHYCTRLREG028 reset 0x70007 — CR\_I3C\_OD\_STA\_STO\_CNT
  [26:16] REGI3CODSTARTHCNT, [10:0] REGI3CODSTOPHCNT
0xE2C I3CPHYCTRLREG02C reset 0x130027 — CR\_I3C\_OD\_SCL\_CNT
  [26:16] REGI3CODHCNT, [10:0] REGI3CODLCNT
0xE30 I3CPHYCTRLREG030 reset 0x130027 — CR\_I3C\_OD\_ACK\_CNT
  [26:16] REGI3CODACKHCNT, [10:0] REGI3CODACKLCNT
0xE34 I3CPHYCTRLREG034 reset 0x10001 — CR\_I3C\_OD\_SDA\_TRAN\_CNT
  [26:16] REGI3CODSDATRANCNT, [10:0] REGI3CODSDAACKTRANCNT
0xE38 I3CPHYCTRLREG038 reset 0x70007 — CR\_I3C\_SDR0\_PP\_SCL\_CNT
  [26:16] REGI3CSDR0PPHCNT, [10:0] REGI3CSDR0PPLCNT
0xE3C I3CPHYCTRLREG03C reset 0x70007 — CR\_I3C\_SDR0\_PP\_TBIT\_CNT
  [26:16] REGI3CSDR0PPTBITHCNT, [10:0] REGI3CSDR0PPTBITLCNT
0xE40 I3CPHYCTRLREG040 reset 0x10001 — CR\_I3C\_SDR0\_PP\_SDA\_TRAN\_CNT
  [26:16] REGI3CSDR0PPSDATRANCNT, [10:0] REGI3CSDR0PPSDATBITTRANCNT
0xE44 I3CPHYCTRLREG044 reset 0x3B0040 — CR\_I3C\_SDR1\_PP\_SCL\_CNT
  [26:16] REGI3CSDR1PPHCNT, [10:0] REGI3CSDR1PPLCNT
0xE48 I3CPHYCTRLREG048 reset 0x3B0040 — CR\_I3C\_SDR1\_PP\_TBIT\_CNT
  [26:16] REGI3CSDR1PPTBITHCNT, [10:0] REGI3CSDR1PPTBITLCNT
0xE4C I3CPHYCTRLREG04C reset 0x10001 — CR\_I3C\_SDR1\_PP\_SDA\_TRAN\_CNT
  [26:16] REGI3CSDR1PPSDATRANCNT, [10:0] REGI3CSDR1PPSDATBITTRANCNT
0xE50 I3CPHYCTRLREG050 reset 0x500055 — CR\_I3C\_SDR2\_PP\_SCL\_CNT
  [26:16] REGI3CSDR2PPHCNT, [10:0] REGI3CSDR2PPLCNT
0xE54 I3CPHYCTRLREG054 reset 0x500055 — CR\_I3C\_SDR2\_PP\_TBIT\_CNT
  [26:16] REGI3CSDR2PPTBITHCNT, [10:0] REGI3CSDR2PPTBITLCNT
0xE58 I3CPHYCTRLREG058 reset 0x10001 — CR\_I3C\_SDR2\_PP\_SDA\_TRAN\_CNT
  [26:16] REGI3CSDR2PPSDATRANCNT, [10:0] REGI3CSDR2PPSDATBITTRANCNT
0xE5C I3CPHYCTRLREG05C reset 0x7C007C — CR\_I3C\_SDR3\_PP\_SCL\_CNT
  [26:16] REGI3CSDR3PPHCNT, [10:0] REGI3CSDR3PPLCNT
0xE60 I3CPHYCTRLREG060 reset 0x7C007C — CR\_I3C\_SDR3\_PP\_TBIT\_CNT
  [26:16] REGI3CSDR3PPTBITHCNT, [10:0] REGI3CSDR3PPTBITLCNT
0xE64 I3CPHYCTRLREG064 reset 0x10001 — CR\_I3C\_SDR3\_PP\_SDA\_TRAN\_CNT
  [26:16] REGI3CSDR3PPSDATRANCNT, [10:0] REGI3CSDR3PPSDATBITTRANCNT
0xE68 I3CPHYCTRLREG068 reset 0xF900F9 — CR\_I3C\_SDR4\_PP\_SCL\_CNT
  [26:16] REGI3CSDR4PPHCNT, [10:0] REGI3CSDR4PPLCNT
0xE6C I3CPHYCTRLREG06C reset 0xF900F9 — CR\_I3C\_SDR4\_PP\_TBIT\_CNT
  [26:16] REGI3CSDR4PPTBITHCNT, [10:0] REGI3CSDR4PPTBITLCNT
0xE70 I3CPHYCTRLREG070 reset 0x10001 — CR\_I3C\_SDR4\_PP\_SDA\_TRAN\_CNT
  [26:16] REGI3CSDR4PPSDATRANCNT, [10:0] REGI3CSDR4PPSDATBITTRANCNT
0xE74 I3CPHYCTRLREG074 reset 0x70007 — CR\_I3C\_DDR\_PP\_SCL\_CNT
  [26:16] REGI3CDDRPPHCNT, [10:0] REGI3CDDRPPLCNT
0xE78 I3CPHYCTRLREG078 reset 0x70007 — CR\_I3C\_DDR\_PP\_TBIT\_CNT
  [26:16] REGI3CDDRPPTBITHCNT, [10:0] REGI3CDDRPPTBITLCNT
0xE7C I3CPHYCTRLREG07C reset 0x10001 — CR\_DDR\_PP\_SDA\_TRAN\_CNT
  [26:16] REGI3CDDRPPSDATRANCNT, [10:0] REGI3CDDRPPSDATBITTRANCNT
0xE80 I3CPHYCTRLREG080 reset 0x4000B — SR\_P\_PREPARE\_SCL\_SDA\_CNT
  [26:16] REGSDAPREPARETRANCNT, [10:0] REGSRPPREPARESCLLCNT
0xE84 I3CPHYCTRLREG084 reset 0x27 — CCR\_TO\_NCR\_OVERLAP\_CNT
  [10:0] REGCRHPOVERLAPCNT
0xE88 I3CPHYCTRLREG088 reset 0x4 — CR\_IBI\_ADDR\_ACK\_PROLONG\_CNT
  [10:0] REGIBIADDRACKPROLONGCNT
0xE8C I3CPHYCTRLREG08C reset 0x11 — TG\_WR\_ADDR\_ACK\_PROLONG
  [31] REGSDRTGWRADDRACKPROLONGEN, [10:0] REGSDRTGWRADDRACKPROLONGCNT
0xE90 I3CPHYCTRLREG090 — TG\_SDA\_TRAN\_CNT
  [26:16] REGTGI3CSDATRANCNT, [10:0] REGTGDDRSDATRANCNT
0xE94 I3CPHYCTRLREG094 reset 0x407 — DDR\_CMD\_HANDOFF\_EARLY\_TM\_CNT
  [15:8] REGDDRHANDOFFCNT, [7:0] REGDDREARLYTMCNT
0xE98 I3CPHYCTRLREG098 reset 0x770077 — CR\_SCL\_SDA\_PULLUP\_EN
  [22:20] REGPPSCLPULLUPEN, [18:16] REGPPSDAPULLUPEN, [14:12] REGODSCLPULLUPEN, [10:8] REGODSDAPULLUPEN, [6:4] REGDDRSCLPULLUPEN, [2:0] REGDDRSDAPULLUPEN
0xE9C I3CPHYCTRLREG09C reset 0x8090909 — SPECIAL\_PATTERN\_SET
  [28] REGI3CSDASTUCKPATAUTOTBITHIGH, [27] REGSDASTUCKPATAUTOHOLD, [26] REGSDASTUCKHOLDSCLHRST, [25] REGTGRSTWITHOUTSTARTSTOP, [24] REGHDREXTWITHOUTSTOP, [23:16] REGI3CSPECIALPATTERNSDAHCNT, [15:8] REGI3CSPECIALPATTERNSDALCNT, [7:0] REGI3CSPECIALPATTERNSCLGOHIGHCNT
0xEA0 I3CPHYCTRLREG0A0 reset 0x20 — SPECIAL\_PATTERN\_SW\_OPT
  [31] REGI3CSPECIALPATTERNSWREQ, [30] REGI3CSPECIALPATTERNSWREQCLR ro, [11] REGTGRSTPRECALC, [10] REGTGRSTSRRECALC, [9] REGTGRSTSDARECALC, [8] REGHDREXTSTOPRECALC, [7:4] REGI3CSPECIALPATTERNSWSPEED, [3:0] REGI3CSPECIALPATTERNSWSEL
0xEA4 I3CPHYCTRLREG0A4 reset 0x3 — SPECIAL\_PATTERN\_SCL\_TOGGLE\_SET
  [17:8] REGI3CSPECIALPATTERNSCLTOGGLEPATREPEAT, [4:0] REGI3CSPECIALPATTERNSCLTOGGLECNT
0xEA8 I3CPHYCTRLREG0A8 reset 0xFFFFFFFF — SPECIAL\_PATTERN\_SCL\_TOGGLE\_PAT
  [31:0] REGI3CSPECIALPATTERNSCLTOGGLESDAPAT
0xEAC I3CPHYCTRLREG0AC reset 0x1E8480 — SPECIAL\_PATTERN\_SCL\_TIEL\_SET
  [31:0] REGI3CSPECIALPATTERNSCLTIELCNT
0xEB4 I3CPHYCTRLREG0B4 reset 0x130704 — SDA\_DETECTOR\_CNT0
  [23:16] REGCNT01US, [15:8] REGCNTBUSFREEPURE, [7:0] REGCNTBUSFREEFMP
0xEB8 I3CPHYCTRLREG0B8 reset 0x90C00C7 — SDA\_DETECTOR\_CNT1
  [31:24] REGCNTBUSAVAL, [23:16] REGCNTBUSFREEFM, [15:0] REGCNTBUSIDLE
0xEBC I3CPHYCTRLREG0BC reset 0x630063 — SDA\_DETECTOR\_CNT2
  [31:16] REGCNTCLOCKSTALLTIMEOUT, [15:0] REGCNTSDADETECTORTIMEOUT
0xEC0 I3CPHYCTRLREG0C0 reset 0x75300708 — SDA\_STUCK\_SET1
  [31:16] REGSDASTUCKHOLDSCLHCNT, [15:8] REGI3CSDASTUCKPATSCLCNT, [7:0] REGI2CSDASTUCKLOWPATSCLCNT
0xEC4 I3CPHYCTRLREG0C4 — SDA\_STUCK\_READ
  [5] REGSCLSTUCK ro, [4] REGSDASTUCKHIGH ro, [3] REGSDASTUCKLOW ro, [2] REGBUSSTOPOK ro, [1] REGSDASYNCI ro, [0] REGSCLSYNCI ro
0xEC8 I3CPHYCTRLREG0C8 — READ\_PHY\_STATE\_MACHINE
  [31:29] REGBUSCOND ro, [28:26] REGRXWORDSTATE ro, [25:22] REGRXSTATE ro, [21:19] REGDDRCRTXWORDSTATE ro, [18:15] REGDDRCRTXSTATE ro, [14:12] REGSDRTGTXSTATE ro, [11:8] REGSDRCRTXWORDSTATE ro, [7:3] REGSDRCRTXSTATE ro, [2:0] REGPHYMODE ro
0xECC I3CPHYCTRLREG0CC reset 0x190 — PHY\_OPTION
  [16] REGTIMERSTDETEN, [15] REGBUSIDLECONDSEL, [14] REGNOHDRMODEDETEN, [13] REGTGTOCRHANDOFFWAITSDARST, [12] REGTGTOCRHANDOFFWAITSCLRST, [11] REGBUSFREETIMECHKEN, [10] REGCRSTOPFAILCHECKEN, [9] REGNEGCLKEN, [8] REGDETIBIMSTINHALTENB, [7] REGPHYAUTOSTOPEN, [6] REGTGI2CMODESDADRIVEEN, [5] REGI3CSDRCRIDLEDRIVEEN, [4] REGTGSTARTDETEN, [3] REGTGABORTRECALCBUSCOND, [2:0] REGDEGLITCHLEVEL
0xED0 I3CPHYCTRLREG0D0 — CR\_SCL\_SDA\_PULLUP\_EN\_ADDITIONAL
  [14:12] REGDDRKPSDAPULLUPEN, [10:8] REGKPSDAPULLUPEN, [6:4] REGIDLESCLPULLUPEN, [2:0] REGIDLESDAPULLUPEN
0xED4 I3CPHYCTRLREG0D4 — SPIKE\_FILTER
  [23:16] REGI2CSPIKEFILTERCNT, [15:8] REGI3CSPIKEFILTERCNT, [5] REGI3CSPIKEFILTERONAFTERTGRSTEN, [4] REGI3CSPIKEFILTEROFFAFTER7ERNW0EN, [3:2] REGI3CSPIKEFILTEREN, [1:0] REGI2CSPIKEFILTEREN
0xED8 I3CPHYCTRLREG0D8 — SCL\_SDA\_TIMMIING\_CNT\_ADDITIONAL
  [26:16] REGSTOPSDAHCNT, [10:0] REGTGI2CSDATRANCNT
0xEDC I3CPHYCTRLREG0DC reset 0x6 — BUS\_FREE\_TIME\_CNT
  [10:0] REGCRSTOPBUSFREECNT
0xEE0 I3CPHYCTRLREG0E0 reset 0xC80109 — SPECIAL\_PATTERN\_SET\_ADDITIONAL
  [25:16] REGTGTOCRHANDOFFWAITCNT, [15:8] REGI3CSPECIALPATTERNSDATRANCNT, [7:0] REGI3CSPECIALPATTERNSETUPCNT
0xEE4 I3CPHYCTRLREG0E4 reset 0xF90 — BUS\_CONTENTION\_CHK0
  [13] REGSDACONTOCCUR ro, [12] REGSCLCONTOCCUR ro, [11] REGBUSCONTTGDDRCRCCHKENB, [10] REGBUSCONTCRDDRFINCHKENB, [9] REGBUSCONTCRDDRCRCLASTBITCHKENB, [8] REGBUSCONTCRDDRCRCCHKENB, [7] REGBUSCONTTGSTARTCHKENB, [6] REGBUSCONTCRSTARTCHKEN, [5] REGBUSCONTDAACHKEN, [4] REGBUSCONTARBADDRCHKENB, [3:0] REGBUSCONTCHKSEL
0xEE8 I3CPHYCTRLREG0E8 — BUS\_CONTENTION\_CNT0
  [26:16] REGCRDDRSDACONTWAIT, [10:0] REGCRSDRSDACONTWAIT
0xEEC I3CPHYCTRLREG0EC — BUS\_CONTENTION\_CNT1
  [26:16] REGTGDDRSDACONTWAIT, [10:0] REGTGSDRSDACONTWAIT
0xEF0 I3CPHYCTRLREG0F0 — BUS\_CONTENTION\_CNT2
  [26:16] REGTGI2CSDACONTWAIT, [10:0] REGCRI2CSDACONTWAIT
0xF00 HCIEXTCAP000 reset 0x401 — HW\_ID\_HEADER
  [23:8] REGHWIDLENGTH ro, [7:0] REGHWIDID ro
0xF04 HCIEXTCAP004 reset 0x3F6 — HW\_ID\_MIPI\_VENDOR
  [31:0] REGHWIDMIPIVENDORID ro
0xF08 HCIEXTCAP008 reset 0x2 — HW\_ID\_I3C\_VER
  [31:0] REGHWIDI3CVERID ro
0xF0C HCIEXTCAP00C — HW\_ID\_I3C\_PRODUCT
  [31:0] REGHWIDI3CPRODUCTID ro
0xF10 HCIEXTCAP010 reset 0x202 — CTL\_CFG\_HEADER
  [23:8] REGCTLCFGLENGTH ro, [7:0] REGCTLCFGID ro
0xF14 HCIEXTCAP014 reset 0x30 — CTL\_CFG\_OPERATION\_MODE
  [5:4] REGCTLCFGOPERATIONMODE ro
0xF18 HCIEXTCAP018 reset 0x4C0 — EXTCAP\_HEADER
  [23:8] REGEXTCAPLENGTH ro, [7:0] REGEXTCAPID ro
0xF1C HCIEXTCAP01C reset 0xD00 — EXTCAP\_CTRL
  [31:0] REGEXTCAPCTRL ro
0xF20 HCIEXTCAP020 reset 0xE00 — EXTCAP\_PHY
  [31:0] REGEXTCAPPHY ro
0xF24 HCIEXTCAP024 reset 0xF80 — EXTCAP\_DMAARB
  [31:0] REGEXTCAPDMAARB ro
0xF80 HCIEXTCAP080 — DMA\_MBUS\_ARB\_CTRL\_0
  [31:0] REGDMAMBUSARBCTRL
0xF84 HCIEXTCAP084 — DMA\_MBUS\_ARB\_CLR\_0
  [0] REGDMAMBUSARBCLR
0xF90 HCIEXTCAP090 — DMA\_MBUS\_ARB\_DBG\_0
  [31:0] REGDMAMBUSARBDBG0 ro
0xF94 HCIEXTCAP094 — DMA\_MBUS\_ARB\_DBG\_1
  [31:0] REGDMAMBUSARBDBG1 ro
0xF98 HCIEXTCAP098 — DMA\_MBUS\_ARB\_DBG\_2
  [31:0] REGDMAMBUSARBDBG2 ro
0xF9C HCIEXTCAP09C — DMA\_MBUS\_ARB\_DBG\_3
  [31:0] REGDMAMBUSARBDBG3 ro
